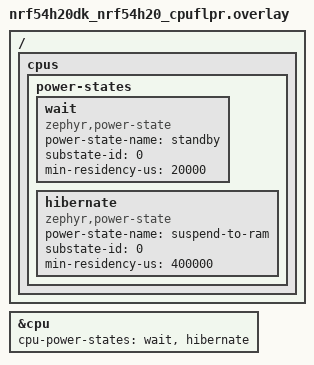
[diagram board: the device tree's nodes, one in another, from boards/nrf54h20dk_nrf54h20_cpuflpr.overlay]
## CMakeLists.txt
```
#
# Copyright (c) 2025 Nordic Semiconductor ASA
#
# SPDX-License-Identifier: LicenseRef-Nordic-5-Clause
#

cmake_minimum_required(VERSION 3.20.0)

find_package(Zephyr REQUIRED HINTS $ENV{ZEPHYR_BASE})
project(remote)

target_sources(app PRIVATE src/main.c)

if(DEFINED CONFIG_SOC_NRF54H20_CPUFLPR)
	message(STATUS "Power Mode handler for RISC V is included.")
	target_sources(app PRIVATE ../../common/power_off.c)
endif()
```

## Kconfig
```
#
# Copyright (c) 2025 Nordic Semiconductor ASA
#
# SPDX-License-Identifier: LicenseRef-Nordic-5-Clause
#

config TEST_SLEEP_DURATION_MS
	int "Core sleep duration (miliseconds)"
	default 1000
	help
	  Set sleep duration to TEST_SLEEP_DURATION_MS miliseconds.
	  Based on the value of 'min-residency-us' specified for each power state defined in the DTS,
	  core enters the lowest possible power state.

config APP_PROVIDE_PM_HOOKS
	bool "Application provides PM hooks"
	default y
	select HAS_PM
	select HAS_POWEROFF

source "Kconfig.zephyr"
```

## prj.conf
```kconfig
CONFIG_LOG=y
CONFIG_CONSOLE=n
CONFIG_UART_CONSOLE=n
CONFIG_SERIAL=n
CONFIG_BOOT_BANNER=n
CONFIG_NCS_BOOT_BANNER=n
CONFIG_PRINTK=n

CONFIG_ASSERT=y

CONFIG_NRF_REGTOOL_VERBOSITY=1
```

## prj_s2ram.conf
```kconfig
CONFIG_PM=y
CONFIG_POWEROFF=y

CONFIG_PM_DEVICE=y
CONFIG_PM_DEVICE_RUNTIME=y

CONFIG_CONSOLE=n
CONFIG_UART_CONSOLE=n
CONFIG_SERIAL=n
CONFIG_BOOT_BANNER=n
CONFIG_NCS_BOOT_BANNER=n

CONFIG_ASSERT=y
```

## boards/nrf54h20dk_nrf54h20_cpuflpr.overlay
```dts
/*
 * Copyright (c) 2025 Nordic Semiconductor ASA
 *
 * SPDX-License-Identifier: LicenseRef-Nordic-5-Clause
 */

/ {
	cpus {
		power-states {
			wait: wait {
				compatible = "zephyr,power-state";
				power-state-name = "standby";
				substate-id = <0>;
				min-residency-us = <20000>;
			};

			hibernate: hibernate {
				compatible = "zephyr,power-state";
				power-state-name = "suspend-to-ram";
				substate-id = <0>;
				min-residency-us = <400000>;
			};
		};
	};
};

&cpu {
	cpu-power-states = <&wait &hibernate>;
};
```

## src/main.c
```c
/*
 * Copyright (c) 2025 Nordic Semiconductor ASA
 *
 * SPDX-License-Identifier: LicenseRef-Nordic-5-Clause
 */
#include <zephyr/kernel.h>

#include <zephyr/logging/log.h>
LOG_MODULE_REGISTER(idle_flpr, LOG_LEVEL_INF);

int main(void)
{
	LOG_INF("Multicore idle_flpr test on %s", CONFIG_BOARD_TARGET);
	LOG_INF("Main sleeps for %d ms", CONFIG_TEST_SLEEP_DURATION_MS);

	return 0;
}
```
